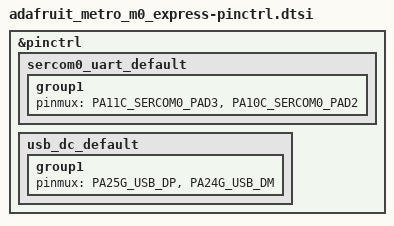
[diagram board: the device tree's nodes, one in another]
/*
 * Copyright (c) 2022, Pieter De Gendt <pieter.degendt@gmail.com>
 * SPDX-License-Identifier: Apache-2.0
 */

#include <dt-bindings/pinctrl/samd21-da1gXabcd-pinctrl.h>

&pinctrl {
	sercom0_uart_default: sercom0_uart_default {
		group1 {
			pinmux = <PA11C_SERCOM0_PAD3>,
				 <PA10C_SERCOM0_PAD2>;
		};
	};

	usb_dc_default: usb_dc_default {
		group1 {
			pinmux = <PA25G_USB_DP>,
				 <PA24G_USB_DM>;
		};
	};
};
